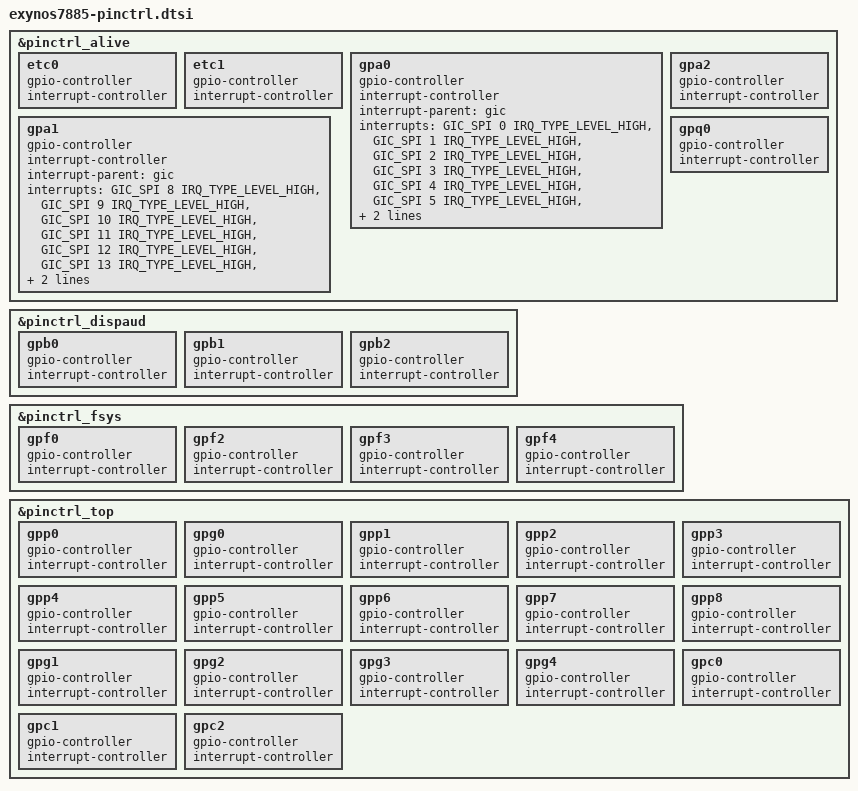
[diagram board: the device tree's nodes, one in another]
// SPDX-License-Identifier: BSD-3-Clause
/*
 * Copyright (c) 2020, Dávid Virág <virag.david003@gmail.com>
 */

&pinctrl_alive {
	etc0: etc0 {
		gpio-controller;
		#gpio-cells = <2>;

		interrupt-controller;
		#interrupt-cells = <2>;
	};

	etc1: etc1 {
		gpio-controller;
		#gpio-cells = <2>;

		interrupt-controller;
		#interrupt-cells = <2>;
	};

	gpa0: gpa0 {
		gpio-controller;
		#gpio-cells = <2>;

		interrupt-controller;
		interrupt-parent = <&gic>;
		#interrupt-cells = <2>;
		interrupts = <GIC_SPI 0 IRQ_TYPE_LEVEL_HIGH>,
			     <GIC_SPI 1 IRQ_TYPE_LEVEL_HIGH>,
			     <GIC_SPI 2 IRQ_TYPE_LEVEL_HIGH>,
			     <GIC_SPI 3 IRQ_TYPE_LEVEL_HIGH>,
			     <GIC_SPI 4 IRQ_TYPE_LEVEL_HIGH>,
			     <GIC_SPI 5 IRQ_TYPE_LEVEL_HIGH>,
			     <GIC_SPI 6 IRQ_TYPE_LEVEL_HIGH>,
			     <GIC_SPI 7 IRQ_TYPE_LEVEL_HIGH>;
	};

	gpa1: gpa1 {
		gpio-controller;
		#gpio-cells = <2>;

		interrupt-controller;
		interrupt-parent = <&gic>;
		#interrupt-cells = <3>;
		interrupts = <GIC_SPI 8 IRQ_TYPE_LEVEL_HIGH>,
			     <GIC_SPI 9 IRQ_TYPE_LEVEL_HIGH>,
			     <GIC_SPI 10 IRQ_TYPE_LEVEL_HIGH>,
			     <GIC_SPI 11 IRQ_TYPE_LEVEL_HIGH>,
			     <GIC_SPI 12 IRQ_TYPE_LEVEL_HIGH>,
			     <GIC_SPI 13 IRQ_TYPE_LEVEL_HIGH>,
			     <GIC_SPI 14 IRQ_TYPE_LEVEL_HIGH>,
			     <GIC_SPI 15 IRQ_TYPE_LEVEL_HIGH>;
	};

	gpa2: gpa2 {
		gpio-controller;
		#gpio-cells = <2>;

		interrupt-controller;
		#interrupt-cells = <2>;
	};

	gpq0: gpq0 {
		gpio-controller;
		#gpio-cells = <2>;

		interrupt-controller;
		#interrupt-cells = <2>;
	};
};

&pinctrl_dispaud {
	gpb0: gpb0 {
		gpio-controller;
		#gpio-cells = <2>;

		interrupt-controller;
		#interrupt-cells = <2>;
	};

	gpb1: gpb1 {
		gpio-controller;
		#gpio-cells = <2>;

		interrupt-controller;
		#interrupt-cells = <2>;
	};

	gpb2: gpb2 {
		gpio-controller;
		#gpio-cells = <2>;

		interrupt-controller;
		#interrupt-cells = <2>;
	};
};

&pinctrl_fsys {
	gpf0: gpf0 {
		gpio-controller;
		#gpio-cells = <2>;

		interrupt-controller;
		#interrupt-cells = <2>;
	};

	gpf2: gpf2 {
		gpio-controller;
		#gpio-cells = <2>;

		interrupt-controller;
		#interrupt-cells = <2>;
	};

	gpf3: gpf3 {
		gpio-controller;
		#gpio-cells = <2>;

		interrupt-controller;
		#interrupt-cells = <2>;
	};

	gpf4: gpf4 {
		gpio-controller;
		#gpio-cells = <2>;

		interrupt-controller;
		#interrupt-cells = <2>;
	};
};

&pinctrl_top {
	gpp0: gpp0 {
		gpio-controller;
		#gpio-cells = <2>;

		interrupt-controller;
		#interrupt-cells = <2>;
	};

	gpg0: gpg0 {
		gpio-controller;
		#gpio-cells = <2>;

		interrupt-controller;
		#interrupt-cells = <2>;
	};

	gpp1: gpp1 {
		gpio-controller;
		#gpio-cells = <2>;

		interrupt-controller;
		#interrupt-cells = <2>;
	};

	gpp2: gpp2 {
		gpio-controller;
		#gpio-cells = <2>;

		interrupt-controller;
		#interrupt-cells = <2>;
	};

	gpp3: gpp3 {
		gpio-controller;
		#gpio-cells = <2>;

		interrupt-controller;
		#interrupt-cells = <2>;
	};

	gpp4: gpp4 {
		gpio-controller;
		#gpio-cells = <2>;

		interrupt-controller;
		#interrupt-cells = <2>;
	};

	gpp5: gpp5 {
		gpio-controller;
		#gpio-cells = <2>;

		interrupt-controller;
		#interrupt-cells = <2>;
	};

	gpp6: gpp6 {
		gpio-controller;
		#gpio-cells = <2>;

		interrupt-controller;
		#interrupt-cells = <2>;
	};

	gpp7: gpp7 {
		gpio-controller;
		#gpio-cells = <2>;

		interrupt-controller;
		#interrupt-cells = <2>;
	};

	gpp8: gpp8 {
		gpio-controller;
		#gpio-cells = <2>;

		interrupt-controller;
		#interrupt-cells = <2>;
	};

	gpg1: gpg1 {
		gpio-controller;
		#gpio-cells = <2>;

		interrupt-controller;
		#interrupt-cells = <2>;
	};

	gpg2: gpg2 {
		gpio-controller;
		#gpio-cells = <2>;

		interrupt-controller;
		#interrupt-cells = <2>;
	};

	gpg3: gpg3 {
		gpio-controller;
		#gpio-cells = <2>;

		interrupt-controller;
		#interrupt-cells = <2>;
	};

	gpg4: gpg4 {
		gpio-controller;
		#gpio-cells = <2>;

		interrupt-controller;
		#interrupt-cells = <2>;
	};

	gpc0: gpc0 {
		gpio-controller;
		#gpio-cells = <2>;

		interrupt-controller;
		#interrupt-cells = <2>;
	};

	gpc1: gpc1 {
		gpio-controller;
		#gpio-cells = <2>;

		interrupt-controller;
		#interrupt-cells = <2>;
	};

	gpc2: gpc2 {
		gpio-controller;
		#gpio-cells = <2>;

		interrupt-controller;
		#interrupt-cells = <2>;
	};
};
